# bao1x register map
Vendor: baochip; File version: 1.0
Registers are 32-bit, read-write, reset 0x0 unless marked. A register's access mark holds for its fields unless they carry their own. Offsets are from the block's base; [hi:lo] are bit positions; {n}, {i} and the like mark numbered series; <NAME> marks a mode.

## BIO_BDMA
Base 0x50124000
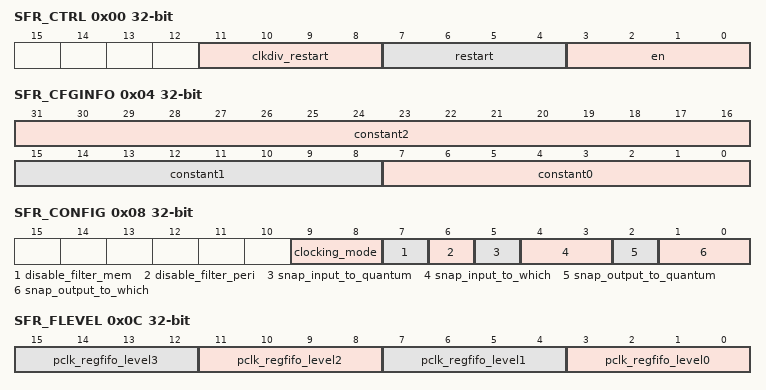
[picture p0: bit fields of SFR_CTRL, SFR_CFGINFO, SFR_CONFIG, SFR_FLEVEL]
0x00 SFR_CTRL — See `bio_bdma.sv#L488 <https://github.com/baochip/baochip-1x/blob/main/rtl/modul es/bio_bdma/rtl/bio_bdma.sv#L488>`__ (line numbers are approximate)
  [11:8] clkdiv_restart — clkdiv_restart read/write control register
  [7:4] restart — restart read/write control register
  [3:0] en — en read/write control register
0x04 SFR_CFGINFO — See `bio_bdma.sv#L489 <https://github.com/baochip/baochip-1x/blob/main/rtl/modul es/bio_bdma/rtl/bio_bdma.sv#L489>`__ (line numbers are approximate)
  [31:16] constant2 — constant value of 4096
  [15:8] constant1 — constant value of 4
  [7:0] constant0 — constant value of 8
0x08 SFR_CONFIG — See `bio_bdma.sv#L490 <https://github.com/baochip/baochip-1x/blob/main/rtl/modul es/bio_bdma/rtl/bio_bdma.sv#L490>`__ (line numbers are approximate)
  [9:8] clocking_mode — clocking_mode read/write control register
  [7] disable_filter_mem — disable_filter_mem read/write control register
  [6] disable_filter_peri — disable_filter_peri read/write control register
  [5] snap_input_to_quantum — snap_input_to_quantum read/write control register
  [4:3] snap_input_to_which — snap_input_to_which read/write control register
  [2] snap_output_to_quantum — snap_output_to_quantum read/write control register
  [1:0] snap_output_to_which — snap_output_to_which read/write control register
0x0C SFR_FLEVEL — See `bio_bdma.sv#L492 <https://github.com/baochip/baochip-1x/blob/main/rtl/modul es/bio_bdma/rtl/bio_bdma.sv#L492>`__ (line numbers are approximate)
  [4n+3:4n] pclk_regfifo_level{n} (n=0..3) — pclk_regfifo_level[{n}] read only status register
{0x10+4i} SFR_TXF{i} (i=0..3) — See `bio_bdma.sv#L{i+493} <https://github.com/baochip/baochip-1x/blob/main/rtl/modul es/bio_bdma/rtl/bio_bdma.sv#L{i+493}>`__ (line numbers are approximate)
  [31:0] fdin — fdin read/write control register
{0x20+4i} SFR_RXF{i} (i=0..3) — See `bio_bdma.sv#L{i+497} <https://github.com/baochip/baochip-1x/blob/main/rtl/modul es/bio_bdma/rtl/bio_bdma.sv#L{i+497}>`__ (line numbers are approximate)
  [31:0] fdout — fdout read only status register
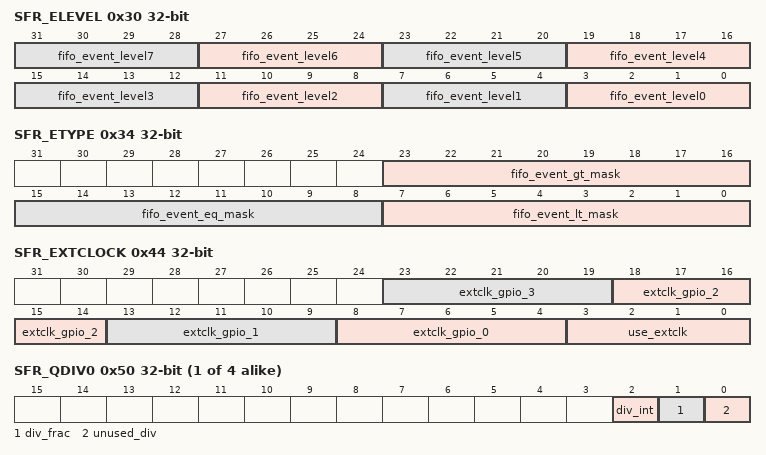
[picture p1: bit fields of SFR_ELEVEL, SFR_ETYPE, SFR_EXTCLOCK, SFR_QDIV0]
0x30 SFR_ELEVEL — See `bio_bdma.sv#L502 <https://github.com/baochip/baochip-1x/blob/main/rtl/modul es/bio_bdma/rtl/bio_bdma.sv#L502>`__ (line numbers are approximate)
  [4n+3:4n] fifo_event_level{n} (n=0..7) — fifo_event_level[{n}] read/write control register
0x34 SFR_ETYPE — See `bio_bdma.sv#L503 <https://github.com/baochip/baochip-1x/blob/main/rtl/modul es/bio_bdma/rtl/bio_bdma.sv#L503>`__ (line numbers are approximate)
  [23:16] fifo_event_gt_mask — fifo_event_gt_mask read/write control register
  [15:8] fifo_event_eq_mask — fifo_event_eq_mask read/write control register
  [7:0] fifo_event_lt_mask — fifo_event_lt_mask read/write control register
0x38 SFR_EVENT_SET — See `bio_bdma.sv#L504 <https://github.com/baochip/baochip-1x/blob/main/rtl/modul es/bio_bdma/rtl/bio_bdma.sv#L504>`__ (line numbers are approximate)
  [23:0] sfr_event_set — sfr_event_set read/write control register
0x3C SFR_EVENT_CLR — See `bio_bdma.sv#L505 <https://github.com/baochip/baochip-1x/blob/main/rtl/modul es/bio_bdma/rtl/bio_bdma.sv#L505>`__ (line numbers are approximate)
  [23:0] sfr_event_clr — sfr_event_clr read/write control register
0x40 SFR_EVENT_STATUS — See `bio_bdma.sv#L506 <https://github.com/baochip/baochip-1x/blob/main/rtl/modul es/bio_bdma/rtl/bio_bdma.sv#L506>`__ (line numbers are approximate)
  [31:0] sfr_event_status — sfr_event_status read only status register
0x44 SFR_EXTCLOCK — See `bio_bdma.sv#L508 <https://github.com/baochip/baochip-1x/blob/main/rtl/modul es/bio_bdma/rtl/bio_bdma.sv#L508>`__ (line numbers are approximate)
  [5n+8:5n+4] extclk_gpio_{n} (n=0..3) — extclk_gpio_{n} read/write control register
  [3:0] use_extclk — use_extclk read/write control register
0x48 SFR_FIFO_CLR — See `bio_bdma.sv#L509 <https://github.com/baochip/baochip-1x/blob/main/rtl/modul es/bio_bdma/rtl/bio_bdma.sv#L509>`__ (line numbers are approximate)
  [3:0] sfr_fifo_clr — sfr_fifo_clr read/write control register
{0x50+4i} SFR_QDIV{i} (i=0..3) — See `bio_bdma.sv#L{i+511} <https://github.com/baochip/baochip-1x/blob/main/rtl/modul es/bio_bdma/rtl/bio_bdma.sv#L{i+511}>`__ (line numbers are approximate)
  [2] div_int — div_int read/write control register
  [1] div_frac — div_frac read/write control register
  [0] unused_div — unused_div read/write control register
0x60 SFR_SYNC_BYPASS — See `bio_bdma.sv#L516 <https://github.com/baochip/baochip-1x/blob/main/rtl/modul es/bio_bdma/rtl/bio_bdma.sv#L516>`__ (line numbers are approximate)
  [31:0] sfr_sync_bypass — sfr_sync_bypass read/write control register
0x64 SFR_IO_OE_INV — See `bio_bdma.sv#L517 <https://github.com/baochip/baochip-1x/blob/main/rtl/modul es/bio_bdma/rtl/bio_bdma.sv#L517>`__ (line numbers are approximate)
  [31:0] sfr_io_oe_inv — sfr_io_oe_inv read/write control register
0x68 SFR_IO_O_INV — See `bio_bdma.sv#L518 <https://github.com/baochip/baochip-1x/blob/main/rtl/modul es/bio_bdma/rtl/bio_bdma.sv#L518>`__ (line numbers are approximate)
  [31:0] sfr_io_o_inv — sfr_io_o_inv read/write control register
0x6C SFR_IO_I_INV — See `bio_bdma.sv#L519 <https://github.com/baochip/baochip-1x/blob/main/rtl/modul es/bio_bdma/rtl/bio_bdma.sv#L519>`__ (line numbers are approximate)
  [31:0] sfr_io_i_inv — sfr_io_i_inv read/write control register
{0x70+4i} SFR_IRQMASK_{i} (i=0..3) — See `bio_bdma.sv#L{i+521} <https://github.com/baochip/baochip-1x/blob/main/rtl/modul es/bio_bdma/rtl/bio_bdma.sv#L{i+521}>`__ (line numbers are approximate)
  [31:0] sfr_irqmask_{i} — sfr_irqmask_{i} read/write control register
0x80 SFR_IRQ_EDGE — See `bio_bdma.sv#L525 <https://github.com/baochip/baochip-1x/blob/main/rtl/modul es/bio_bdma/rtl/bio_bdma.sv#L525>`__ (line numbers are approximate)
  [3:0] sfr_irq_edge — sfr_irq_edge read/write control register
0x84 SFR_DBG_PADOUT — See `bio_bdma.sv#L526 <https://github.com/baochip/baochip-1x/blob/main/rtl/modul es/bio_bdma/rtl/bio_bdma.sv#L526>`__ (line numbers are approximate)
  [31:0] sfr_dbg_padout — sfr_dbg_padout read only status register
0x88 SFR_DBG_PADOE — See `bio_bdma.sv#L527 <https://github.com/baochip/baochip-1x/blob/main/rtl/modul es/bio_bdma/rtl/bio_bdma.sv#L527>`__ (line numbers are approximate)
  [31:0] sfr_dbg_padoe — sfr_dbg_padoe read only status register
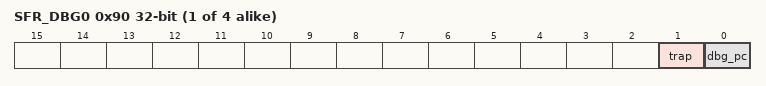
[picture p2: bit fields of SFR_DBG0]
{0x90+4i} SFR_DBG{i} (i=0..3) — See `bio_bdma.sv#L{i+529} <https://github.com/baochip/baochip-1x/blob/main/rtl/modul es/bio_bdma/rtl/bio_bdma.sv#L{i+529}>`__ (line numbers are approximate)
  [1] trap — trap read only status register
  [0] dbg_pc — dbg_pc read only status register
0xA0 SFR_MEM_GUTTER — See `bio_bdma.sv#L535 <https://github.com/baochip/baochip-1x/blob/main/rtl/modul es/bio_bdma/rtl/bio_bdma.sv#L535>`__ (line numbers are approximate)
  [31:0] sfr_mem_gutter — sfr_mem_gutter read/write control register
0xA4 SFR_PERI_GUTTER — See `bio_bdma.sv#L536 <https://github.com/baochip/baochip-1x/blob/main/rtl/modul es/bio_bdma/rtl/bio_bdma.sv#L536>`__ (line numbers are approximate)
  [31:0] sfr_peri_gutter — sfr_peri_gutter read/write control register
{0xB0+4i} SFR_DMAREQ_MAP_CR_EVMAP{i} (i=0..5) — See `bio_bdma.sv#L571 <https://github.com/baochip/baochip-1x/blob/main/rtl/modul es/bio_bdma/rtl/bio_bdma.sv#L571>`__ (line numbers are approximate)
  [31:0] cr_evmap{i} — cr_evmap read/write control register
{0xC8+4i} SFR_DMAREQ_STAT_SR_EVSTAT{i} (i=0..5) — See `bio_bdma.sv#L572 <https://github.com/baochip/baochip-1x/blob/main/rtl/modul es/bio_bdma/rtl/bio_bdma.sv#L572>`__ (line numbers are approximate)
  [31:0] sr_evstat{i} — sr_evstat read only status register
{0xE0+8i} SFR_FILTER_BASE_{i} (i=0..3) — See `bio_bdma.sv#L{2i+593} <https://github.com/baochip/baochip-1x/blob/main/rtl/modul es/bio_bdma/rtl/bio_bdma.sv#L{2i+593}>`__ (line numbers are approximate)
  [19:0] filter_base — filter_base read/write control register
{0xE4+8i} SFR_FILTER_BOUNDS_{i} (i=0..3) — See `bio_bdma.sv#L{2i+594} <https://github.com/baochip/baochip-1x/blob/main/rtl/modul es/bio_bdma/rtl/bio_bdma.sv#L{2i+594}>`__ (line numbers are approximate)
  [19:0] filter_bounds — filter_bounds read/write control register
